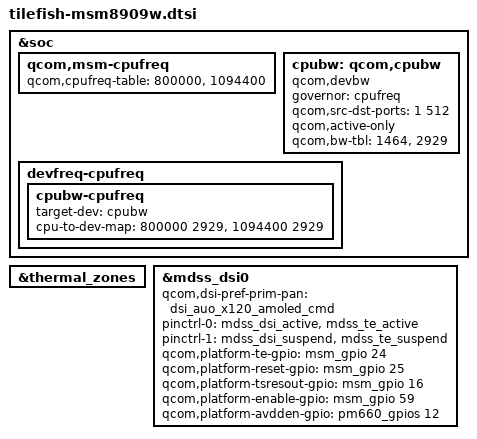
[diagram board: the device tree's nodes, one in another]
/* Copyright (c) 2015-2018, The Linux Foundation. All rights reserved.
 *
 * This program is free software; you can redistribute it and/or modify
 * it under the terms of the GNU General Public License version 2 and
 * only version 2 as published by the Free Software Foundation.
 *
 * This program is distributed in the hope that it will be useful,
 * but WITHOUT ANY WARRANTY; without even the implied warranty of
 * MERCHANTABILITY or FITNESS FOR A PARTICULAR PURPOSE.  See the
 * GNU General Public License for more details.
 */

&soc {
	qcom,msm-cpufreq {
		/delete-property/ qcom,cpufreq-table;
		qcom,cpufreq-table =
			<  800000 >,
			< 1094400 >;
	};
	/delete-node/ qcom,cpubw;
	cpubw: qcom,cpubw {
		compatible = "qcom,devbw";
		governor = "cpufreq";
		qcom,src-dst-ports = <1 512>;
		qcom,active-only;
		qcom,bw-tbl =
			< 1464 /* 192 MHz */>,
			< 2929 /* 384 MHz */>;
	};
	/delete-node/ devfreq-cpufreq;
	devfreq-cpufreq {
		cpubw-cpufreq {
			target-dev = <&cpubw>;
			cpu-to-dev-map =
				<  800000  2929>,
				< 1094400  2929>;
		};
	};
};

&thermal_zones {
	/delete-node/ case-therm-step;
};

&mdss_dsi0 {
	qcom,dsi-pref-prim-pan = <&dsi_auo_x120_amoled_cmd>;
	pinctrl-names = "mdss_default", "mdss_sleep";
	pinctrl-0 = <&mdss_dsi_active &mdss_te_active>;
	pinctrl-1 = <&mdss_dsi_suspend &mdss_te_suspend>;

	qcom,platform-te-gpio = <&msm_gpio 24 0>;
	qcom,platform-reset-gpio = <&msm_gpio 25 0>;
	qcom,platform-tsresout-gpio = <&msm_gpio 16 0>;
	qcom,platform-enable-gpio = <&msm_gpio 59 0>;
	qcom,platform-avdden-gpio = <&pm660_gpios 12 0>;
	/delete-property/ qcom,platform-bklight-en-gpio;
};
